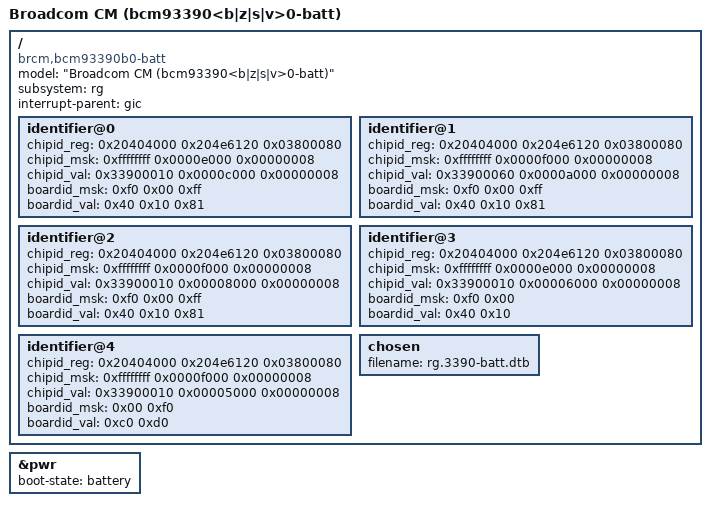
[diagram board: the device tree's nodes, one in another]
/dts-v1/;

/ {
	model = "Broadcom CM (bcm93390<b|z|s|v>0-batt)";
	compatible = "brcm,bcm93390b0-batt", "brcm,bcm93390z0-batt", "brcm,bcm93390s0-batt", "brcm,bcm93390v0-batt",
		     "brcm,bcm3390b0-batt", "brcm,bcm3390z0-batt", "brcm,bcm3390s0-batt", "brcm,bcm3390v0-batt",
		     "brcm,bcm3390-batt",
		     "brcm,bcm3390",
		     "brcm,brcmcm", "brcm,brcmstb";
	subsystem = "rg";
	#address-cells = <0x2>;
	#size-cells = <0x2>;
	interrupt-parent = <&gic>;

	identifier@0 {
			    /*			     BMU mbox0: */
			    /* chip id    mfg id     on battery */
		chipid_reg = < 0x20404000 0x204e6120 0x03800080 >;
		chipid_msk = < 0xffffffff 0x0000e000 0x00000008 >;
		chipid_val = < 0x33900010 0x0000c000 0x00000008 >;
			     /*
			      * Only boards supporting battery. Can't rely on
			      * BMU's mbox0 power state on non-battery boards.
			      */
			     /* SMWVG  SV     VCM  */
		boardid_msk = < 0xf0   0x00   0xff >;
		boardid_val = < 0x40   0x10   0x81 >;
	};

	identifier@1 {
			    /*			     BMU mbox0: */
			    /* chip id    mfg id     on battery */
		chipid_reg = < 0x20404000 0x204e6120 0x03800080 >;
		chipid_msk = < 0xffffffff 0x0000f000 0x00000008 >;
		chipid_val = < 0x33900060 0x0000a000 0x00000008 >;
			     /*
			      * Only boards supporting battery. Can't rely on
			      * BMU's mbox0 power state on non-battery boards.
			      */
			     /* SMWVG  SV     VCM  */
		boardid_msk = < 0xf0   0x00   0xff >;
		boardid_val = < 0x40   0x10   0x81 >;
	};

	identifier@2 {
			    /*			     BMU mbox0: */
			    /* chip id    mfg id     on battery */
		chipid_reg = < 0x20404000 0x204e6120 0x03800080 >;
		chipid_msk = < 0xffffffff 0x0000f000 0x00000008 >;
		chipid_val = < 0x33900010 0x00008000 0x00000008 >;
			     /*
			      * Only boards supporting battery. Can't rely on
			      * BMU's mbox0 power state on non-battery boards.
			      */
			     /* SMWVG  SV     VCM  */
		boardid_msk = < 0xf0   0x00   0xff >;
		boardid_val = < 0x40   0x10   0x81 >;
	};

	identifier@3 {
			    /*			     BMU mbox0: */
			    /* chip id    mfg id     on battery */
		chipid_reg = < 0x20404000 0x204e6120 0x03800080 >;
		chipid_msk = < 0xffffffff 0x0000e000 0x00000008 >;
		chipid_val = < 0x33900010 0x00006000 0x00000008 >;
			     /*
			      * Only boards supporting battery. Can't rely on
			      * BMU's mbox0 power state on non-battery boards.
			      */
			     /* SMWVG  SV   */
		boardid_msk = < 0xf0   0x00 >;
		boardid_val = < 0x40   0x10 >;
	};

	identifier@4 {
			    /*			     BMU mbox0: */
			    /* chip id    mfg id     on battery */
		chipid_reg = < 0x20404000 0x204e6120 0x03800080 >;
		chipid_msk = < 0xffffffff 0x0000f000 0x00000008 >;
		chipid_val = < 0x33900010 0x00005000 0x00000008 >;
			     /*
			      * Only boards supporting battery. Can't rely on
			      * BMU's mbox0 power state on non-battery boards.
			      */
			     /* VSV  VVCM */
		boardid_msk = < 0x00 0xf0 >;
		boardid_val = < 0xc0 0xd0 >;
	};
};

/include/ "rg.3390b0-bolt.dtsi"
/include/ "rg.3390-base.dtsi"
/include/ "rg.3390-batt.dtsi"

/********************************************************************
 * any nodes that appear below are platform specific additions and
 * replacements.
 * The dtc will add or replace any properties in the nodes
 * below to the same nodes that appear in include files above.
 * If the property does not exist in the node above it will be added.
 * If the property does exist it will replace it.
 ********************************************************************/

&pwr {
	boot-state = "battery";
};

/ {
	chosen {
		filename = "rg.3390-batt.dtb";
	};
};
